# AT32F415xx_v2 register map
Vendor: Keil; Series: AT32F415; File version: 1.0
CPU: CM4 r0p1, little endian, no MPU, FPU, 4 interrupt priority bits
Registers are 32-bit, read-write, reset 0x0 unless marked. A register's access mark holds for its fields unless they carry their own. Offsets are from the block's base; [hi:lo] are bit positions.

## WDT — Watchdog
Base 0x40003000
0x00 CMD — Command register
  [15:0] CMD
0x04 DIV — Division register
  [2:0] DIV — Division divider
0x08 RLD reset 0xFFF — Reload register
  [11:0] RLD — Reload value
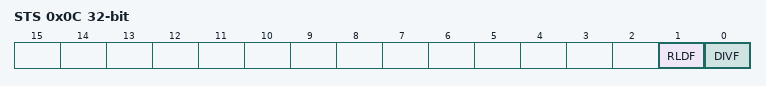
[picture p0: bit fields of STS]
0x0C STS — Status register
  [1] RLDF — Reload value update complete flag
  [0] DIVF — Division value update complete flag

## WWDT — Window watchdog
Base 0x40002C00
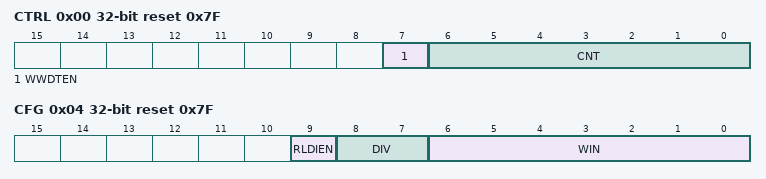
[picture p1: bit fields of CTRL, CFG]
0x00 CTRL reset 0x7F — Control register
  [7] WWDTEN — Window watchdog enable
  [6:0] CNT — Decrement counter
0x04 CFG reset 0x7F — Configuration register
  [9] RLDIEN — Reload counter interrupt
  [8:7] DIV — Clock division value
  [6:0] WIN — Window value
0x08 STS — Status register
  [0] RLDF — Reload counter interrupt flag

## TMR9 — General purpose timer
Base 0x40014C00
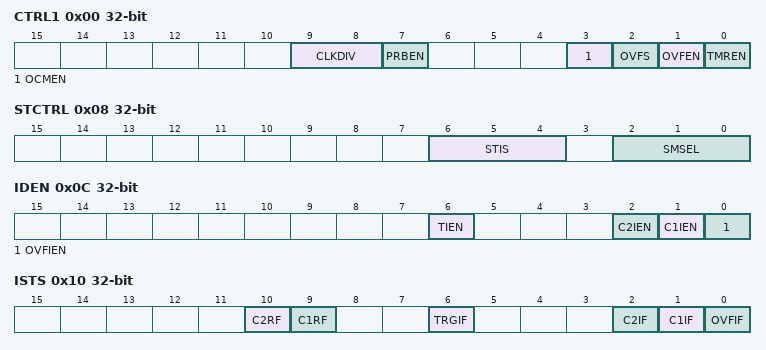
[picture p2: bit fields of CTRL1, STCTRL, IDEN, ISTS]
0x00 CTRL1 — Control register 1
  [9:8] CLKDIV — Clock divider
  [7] PRBEN — Period buffer enable
  [3] OCMEN — One cycle mode enable
  [2] OVFS — Overflow event source
  [1] OVFEN — Overflow event enable
  [0] TMREN — TMR enable
0x08 STCTRL — Subordinate TMR control register
  [6:4] STIS — Subordinate TMR input selection
  [2:0] SMSEL — Subordinate TMR mode selection
0x0C IDEN — Interrupt/DMA enable register
  [6] TIEN — Trigger interrupt enable
  [2] C2IEN — Channel 2 interrupt enable
  [1] C1IEN — Channel 1 interrupt enable
  [0] OVFIEN — Overflow interrupt enable
0x10 ISTS — Interrupt status register
  [10] C2RF — Channel 2 recapture flag
  [9] C1RF — Channel 1 recapture flag
  [6] TRGIF — Trigger interrupt flag
  [2] C2IF — Channel 2 interrupt flag
  [1] C1IF — Channel 1 interrupt flag
  [0] OVFIF — Overflow interrupt flag
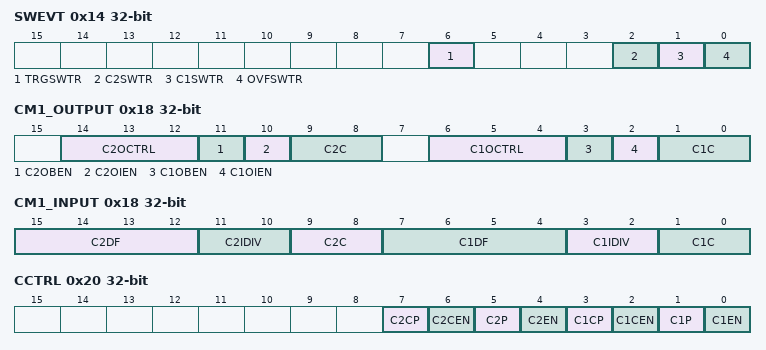
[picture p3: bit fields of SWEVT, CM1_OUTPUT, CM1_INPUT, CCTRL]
0x14 SWEVT — Software event register
  [6] TRGSWTR — Trigger event triggered by software
  [2] C2SWTR — Channel 2 event triggered by software
  [1] C1SWTR — Channel 1 event triggered by software
  [0] OVFSWTR — Overflow event triggered by software
0x18 CM1_OUTPUT — Channel output mode register
  [14:12] C2OCTRL — Channel 2 output control
  [11] C2OBEN — Channel 2 output buffer enable
  [10] C2OIEN — Channel 2 output immediately enable
  [9:8] C2C — Channel 2 configure
  [6:4] C1OCTRL — Channel 1 output control
  [3] C1OBEN — Channel 1 output buffer enable
  [2] C1OIEN — Channel 1 output immediately enable
  [1:0] C1C — Channel 1 configure
0x18 CM1_INPUT (alternate view of CM1_OUTPUT) — Channel input mode register 1
  [15:12] C2DF — Channel 2 digital filter
  [11:10] C2IDIV — Channel 2 input divider
  [9:8] C2C — Channel 2 configure
  [7:4] C1DF — Channel 1 digital filter
  [3:2] C1IDIV — Channel 1 input divider
  [1:0] C1C — Channel 1 configure
0x20 CCTRL — Channel control register
  [7] C2CP — Channel 2 complementary polarity
  [6] C2CEN — Channel 2 complementary enable
  [5] C2P — Channel 2 Polarity
  [4] C2EN — Channel 2 enable
  [3] C1CP — Channel 1 complementary polarity
  [2] C1CEN — Channel 1 complementary enable
  [1] C1P — Channel 1 Polarity
  [0] C1EN — Channel 1 enable
0x24 CVAL — Counter value
  [15:0] CVAL
0x28 DIV — Divider value
  [15:0] DIV
0x2C PR — Period value
  [15:0] PR
0x34 C1DT — Channel 1 data register
  [15:0] C1DT
0x38 C2DT — Channel 2 data register
  [15:0] C2DT

## TMR10 — General purpose timer
Base 0x40015000
Same registers: TMR11 0x40015400
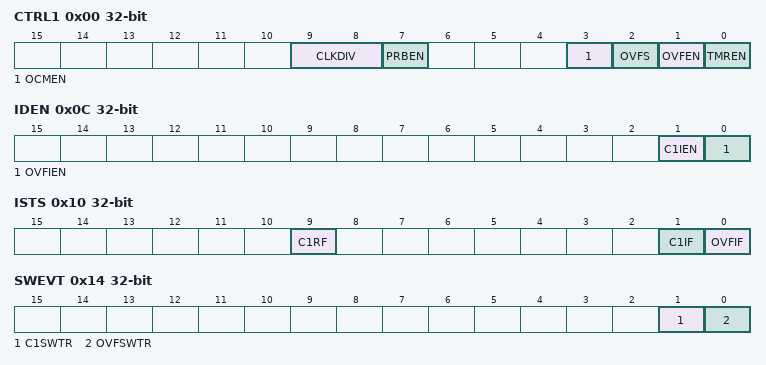
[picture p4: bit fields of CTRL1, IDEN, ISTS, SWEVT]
0x00 CTRL1 — Control register 1
  [9:8] CLKDIV — Clock divider
  [7] PRBEN — Period buffer enable
  [3] OCMEN — One cycle mode enable
  [2] OVFS — Overflow event source
  [1] OVFEN — Overflow event enable
  [0] TMREN — TMR enable
0x0C IDEN — Interrupt/DMA enable register
  [1] C1IEN — Channel 1 interrupt enable
  [0] OVFIEN — Overflow interrupt enable
0x10 ISTS — Interrupt status register
  [9] C1RF — Channel 1 recapture flag
  [1] C1IF — Channel 1 interrupt flag
  [0] OVFIF — Overflow interrupt flag
0x14 SWEVT — Software event register
  [1] C1SWTR — Channel 1 event triggered by software
  [0] OVFSWTR — Overflow event triggered by software
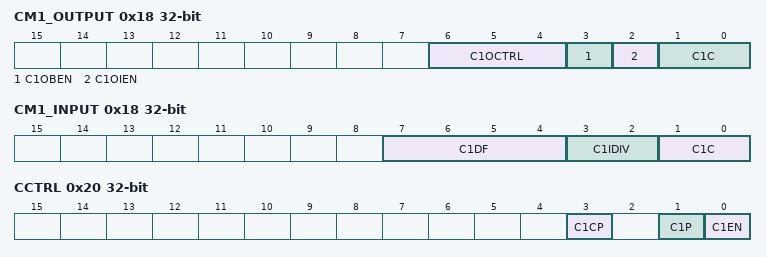
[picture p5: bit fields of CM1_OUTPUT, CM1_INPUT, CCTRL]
0x18 CM1_OUTPUT — Channel output mode register
  [6:4] C1OCTRL — Channel 1 output control
  [3] C1OBEN — Channel 1 output buffer enable
  [2] C1OIEN — Channel 1 output immediately enable
  [1:0] C1C — Channel 1 configure
0x18 CM1_INPUT (alternate view of CM1_OUTPUT) — Channel input mode register 1
  [7:4] C1DF — Channel 1 digital filter
  [3:2] C1IDIV — Channel 1 input divider
  [1:0] C1C — Channel 1 configure
0x20 CCTRL — Channel control register
  [3] C1CP — Channel 1 complementary polarity
  [1] C1P — Channel 1 Polarity
  [0] C1EN — Channel 1 enable
0x24 CVAL — Counter value
  [15:0] CVAL
0x28 DIV — Divider value
  [15:0] DIV
0x2C PR — Period value
  [15:0] PR
0x34 C1DT — Channel 1 data register
  [15:0] C1DT
